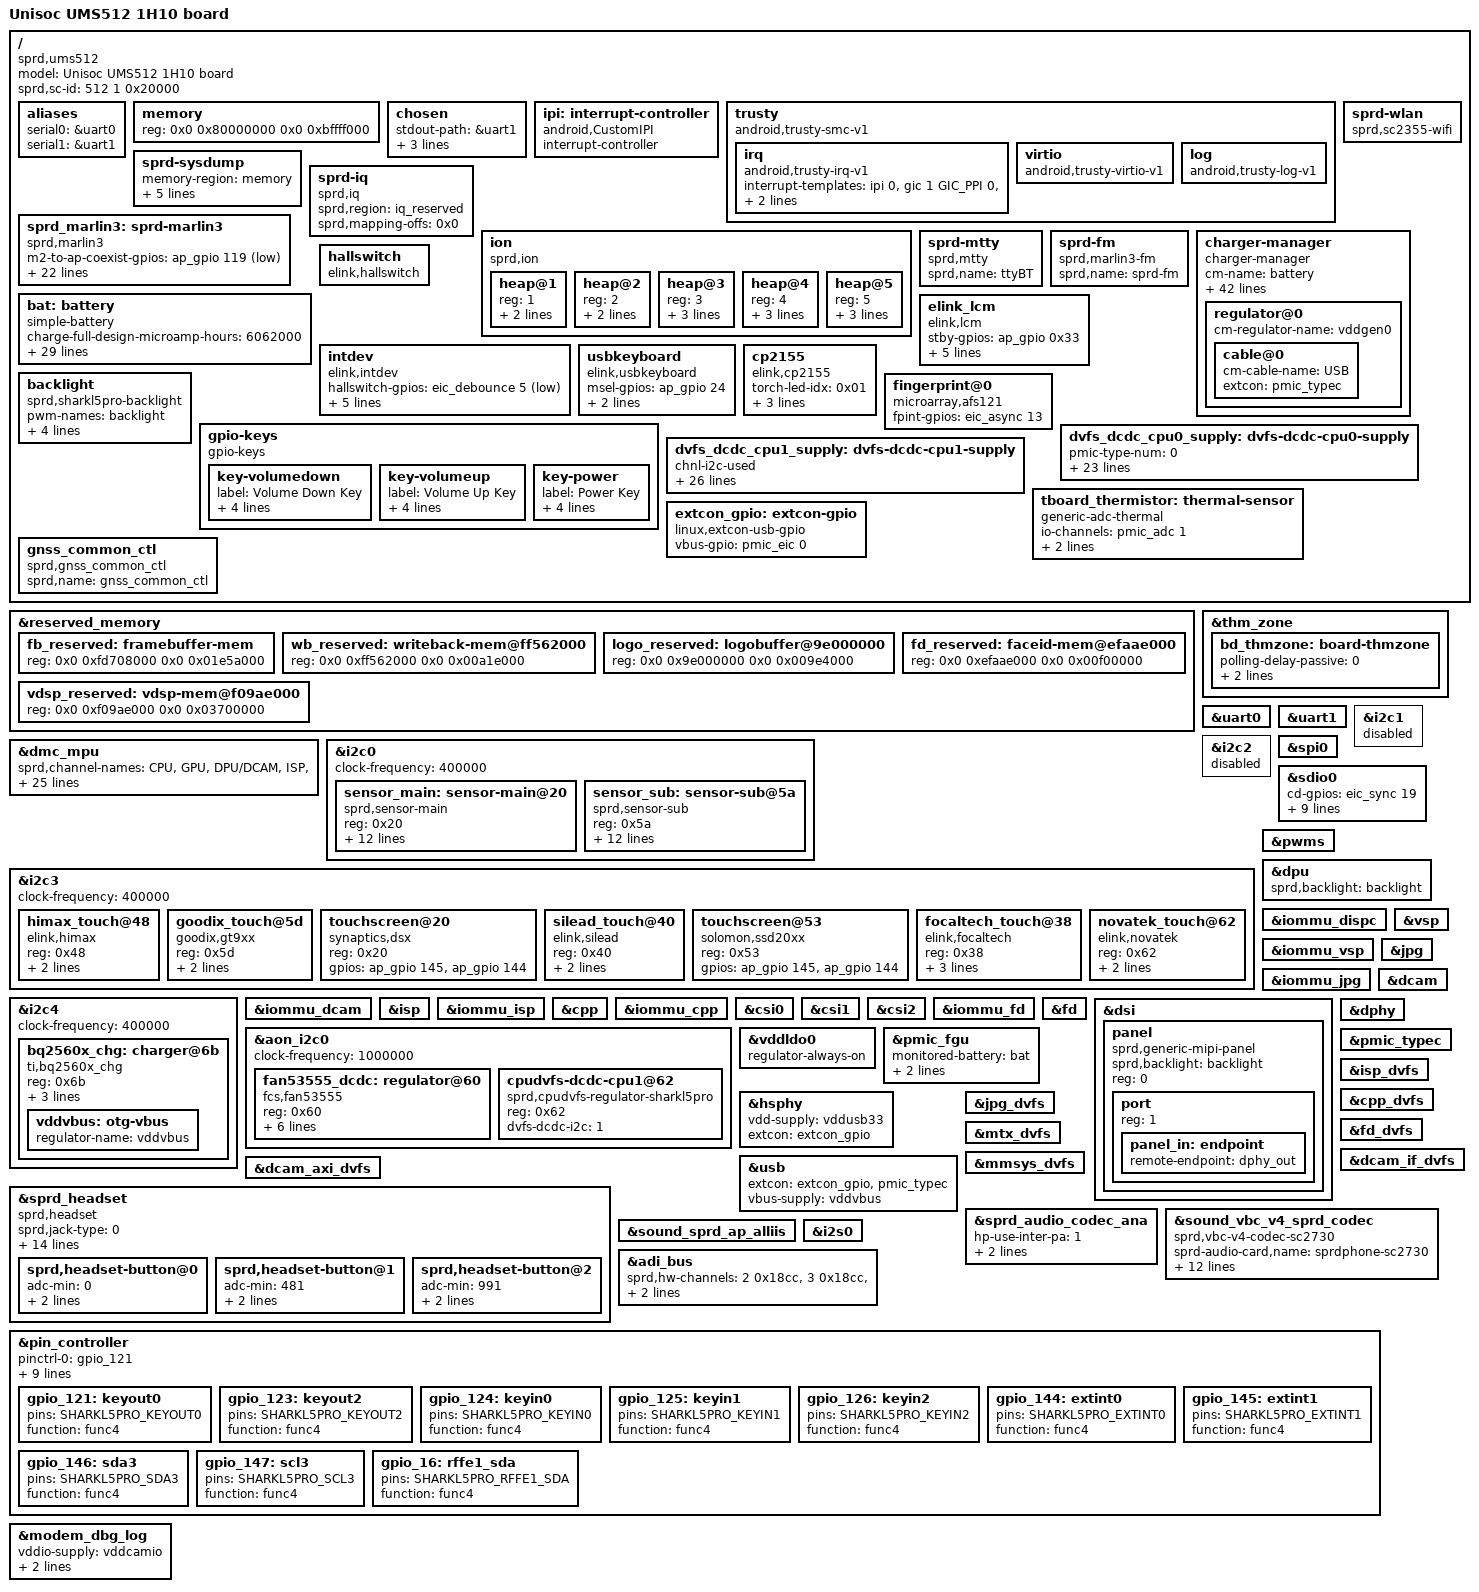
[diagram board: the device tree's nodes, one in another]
// SPDX-License-Identifier: (GPL-2.0+ OR MIT)
/*
 * Unisoc Sharkl5Pro platform DTS file
 *
 * Copyright (C) 2018, Unisoc Communications Inc.
 */

/dts-v1/;

#include <dt-bindings/gpio/gpio.h>
#include <dt-bindings/input/input.h>
#include <dt-bindings/interrupt-controller/irq.h>
#include "aidata-ums512.dtsi"
#include "ums512-t610dvfs.dtsi"
#include "ums512-t618dvfs.dtsi"
#include "sc2730.dtsi"
#include "ums512-mach.dtsi"
#include "ums512-modem.dtsi"
#include "aidata-lcd.dtsi"
#include "sprd-sound-fe-be.dtsi"
#include "extra_sound_card_component.dtsi"

/ {
	model = "Unisoc UMS512 1H10 board";

	compatible = "sprd,ums512";

	sprd,sc-id = <512 1 0x20000>;

	aliases {
		serial0 = &uart0;
		serial1 = &uart1;
	};

/* 3 GB */
	memory: memory {
		device_type = "memory";
		reg = <0x0 0x80000000 0x0 0xbffff000>;
	};

	chosen {
		stdout-path = &uart1;
		bootargs = "earlycon=sprd_serial,0x70100000,115200n8 console=ttyS1,115200n8 loglevel=8 init=/init root=/dev/ram0 rw androidboot.hardware=ums512_1h10 androidboot.dtbo_idx=0 printk.devkmsg=on androidboot.boot_devices=soc/soc:ap-apb/71400000.sdio swiotlb=1 lcd_id=ID8006 lcd_name=tv101wum_ll2_wuxga lcd_base=9e000000 lcd_size=1920x1200 pixel_clock=153600000 logo_bpix=24 androidboot.ddrsize=3072M androidboot.ddrsize.range=[2048,) androidboot.lwfq.type=1 androidboot.auto.efuse=T610 androidboot.auto.chipid=UMS512-AC  sysdump_magic=85500000 modem=shutdown ltemode=lcsfb rfboard.id=0 rfhw.id=32816 crystal=6 32k.less=1 marlin.clktype=1 androidboot.pmic.chipid=2730 modemboot.method=emmcboot  androidboot.verifiedbootstate=orange androidboot.flash.locked=0  androidboot.serialno=AU13T31J045675 androidboot.vbmeta.device=PARTUUID=1.0";
		elink_bootmode = "2";
	};

	ipi: interrupt-controller {
		compatible = "android,CustomIPI";
		#interrupt-cells = <1>;
		interrupt-controller;
	};

	trusty {
		compatible = "android,trusty-smc-v1";
		irq {
			compatible = "android,trusty-irq-v1";
			interrupt-templates = <&ipi 0>,
				<&gic 1 GIC_PPI 0>,
				<&gic 1 GIC_SPI 0>;
			interrupt-ranges = < 0  15 0>,
					<16  31 1>,
					<32 223 2>;
		};

		virtio {
			compatible = "android,trusty-virtio-v1";
		};

		log {
			compatible = "android,trusty-log-v1";
		};
	};
	sprd-sysdump {
		memory-region = <&memory>;
		memory-region-re = <&ddrbist_reserved>, <&cp_reserved>, <&smem_reserved>, <&sensorhub_reserved>, <&scproc_pubpm>, <&audio_reserved>, <&audiodsp_reserved>;
		memory-region-se = <&tos_reserved>, <&sml_reserved>;
	};

	sprd-iq {
		compatible = "sprd,iq";
		sprd,region = <&iq_reserved>;
		sprd,mapping-offs = <0x0>;
	};

	ion: ion {
		compatible = "sprd,ion";
		#address-cells = <1>;
		#size-cells = <0>;

		heap@1 {
			reg = <1>;
			label = "carveout_mm";
			type = <2>;
		};

		heap@2 {
			reg = <2>;
			label = "carveout_overlay";
			type = <2>;
		};

		heap@3 {
			reg = <3>;
			label = "carveout_fb";
			type = <2>;
			memory-region = <&fb_reserved>;
		};

		heap@4 {
			reg = <4>;
			label = "carveout_fd";
			type = <2>;
			memory-region = <&fd_reserved>;
		};

		heap@5 {
			reg = <5>;
			label = "carveout_vdsp";
			type = <2>;
			memory-region = <&vdsp_reserved>;
		};
	};

	sprd-wlan {
		compatible = "sprd,sc2355-wifi";
	};

	sprd_marlin3: sprd-marlin3 {
		compatible = "sprd,marlin3";
		m2-to-ap-coexist-gpios = <&ap_gpio 119 GPIO_ACTIVE_LOW>;
		m2-wakeup-ap-gpios = <&ap_gpio 32 GPIO_ACTIVE_LOW>;
		permit-ap-send-gpios = <&ap_gpio 121 GPIO_ACTIVE_LOW>;
		reset-gpios = <&ap_gpio 95 GPIO_ACTIVE_LOW>;
		enable-gpios = <&ap_gpio 143 GPIO_ACTIVE_LOW>;
		m2-to-ap-irq-gpios = <&ap_gpio 94 GPIO_ACTIVE_LOW>;
		avdd12-supply = <&vddwcn>;
		avdd33-supply = <&vddwifipa>;
		dcxo18-supply = <&vddsim2>;

		clock-names = "clk_32k", "source", "enable";
		clocks = <&aon_clk CLK_AUX0>,
		<&ext_32k>,
		<&aonapb_gate CLK_AUX0_EB>;

		sdhci-name = <&sdio1>;
		sprd,btwf-file-name = "/dev/block/platform/soc/soc:ap-apb/71400000.sdio/by-name/wcnmodem";
		sprd,gnss-file-name = "/dev/block/platform/soc/soc:ap-apb/71400000.sdio/by-name/gnssmodem";
		adma-tx;
		adma-rx;
		/*
		 * bound parameter:
		 * [0]:addr offset, [1]:mask, [2]:unboundval, [3]:boundval
		 */
		avdd12-parent-bound-chip = <0x1a4c 0x1 0x0 0x1>;
		avdd12-bound-wbreq = <0x1ac8 0x1000 0x0 0x1000>;
		avdd33-bound-wbreq = <0x1acc 0x4 0x0 0x4>;
		post-power-on-delay-ms = <20>;
		/* stock U-Boot passes marlin.clktype=1 (TSX); U-Boot here does not */
		xtal-26m-clk-type = "TSX";
	};

	sprd-mtty {
		compatible = "sprd,mtty";
		sprd,name = "ttyBT";
	};

	sprd-fm {
		compatible = "sprd,marlin3-fm";
		sprd,name = "sprd-fm";
	};

	bat: battery {
		compatible = "simple-battery";
		charge-full-design-microamp-hours = <6062000>;
		charge-term-current-microamp = <240000>;
		constant_charge_current_max_microamp = <240000>;
		constant_charge_voltage_max_microvolt = <4352000>;
		factory-internal-resistance-micro-ohms = <88000>;
		voltage-min-design-microvolt = <3450000>;
		ocv-capacity-celsius = <20>;

		ocv-capacity-table-0 = <4311000 100>, <4246000 95>, <4190000 90>,
		<4137000 85>, <4086000 80>, <4039000 75>,
		<3981000 70>, <3955000 65>, <3912000 60>,
		<3867000 55>, <3839000 50>, <3818000 45>,
		<3802000 40>, <3789000 35>, <3777000 30>,
		<3763000 25>, <3746000 20>, <3723000 15>,
		<3696000 10>, <3681000 5>, <3400000 0>;

		capacity-temp-table = <45 99>, <25 100>, <10 100>, <0 100>,
		<(-10) 91>, <(-20) 70>;

		resistance-temp-table = <45 68>, <25 88>, <10 280>, <0 428>,
		<(-10) 1181>, <(-20) 1403>;

		voltage-temp-table = <1066000 800>, <959000 850>, <855000 900>,
		<754000 950>, <660000 1000>, <574000 1050>,
		<497000 1100>, <428000 1150>, <368000 1200>,
		<316000 1250>, <271000 1300>, <232000 1350>,
		<199000 1400>, <170000 1450>, <146000 1500>,
		<126000 1550>, <108000 1600>, <94000 1650>;

		charge-sdp-current-microamp = <500000 500000>;
		charge-dcp-current-microamp = <2000000 2000000>;
		charge-cdp-current-microamp = <1150000 1150000>;
		charge-unknown-current-microamp = <2000000 2000000>;
	};

	charger-manager {
		compatible = "charger-manager";
		cm-name = "battery";
		cm-poll-mode = <2>;
		cm-poll-interval = <15000>;
		cm-battery-stat = <2>;
		cm-capacity-track;

		monitored-battery = <&bat>;

		cm-fullbatt-vchkdrop-ms = <30000>;
		cm-fullbatt-vchkdrop-volt = <60000>;
		cm-fullbatt-voltage = <4352000>;
		cm-fullbatt-current = <240000>;
		cm-fullbatt-capacity = <100>;

		cm-num-chargers = <1>;
		cm-chargers = "bq2560x_charger";
		cm-fuel-gauge = "sc27xx-fgu";

		cm-battery-cold = <0>;
		cm-battery-cold-in-minus;
		cm-battery-hot = <500>;
		cm-battery-temp-diff = <100>;

		cm-charging-max = <21600000>;
		cm-discharging-max = <2700000>;

		cm-wdt-interval = <60>;

		cm-shutdown-voltage = <3100000>;

		cm-tickle-time-out = <1500>;
		cm-one-cap-time = <30>;

		cm-charge-voltage-max = <6500000>;
		cm-charge-voltage-drop = <700000>;

		cm-sdp-jeita-temp-table = <1000 1030 0 4352000>,
		<1150 1180 500000 4352000>,
		<1450 1420 500000 4352000>,
		<1600 1570 500000 4100000>;

		cm-cdp-jeita-temp-table = <1000 1030 0 4352000>,
		<1150 1180 700000 4352000>,
		<1450 1420 1150000 4352000>,
		<1600 1570 700000 4100000>;

		cm-dcp-jeita-temp-table = <1000 1030 0 4352000>,
		<1150 1180 700000 4352000>,
		<1450 1420 2000000 4352000>,
		<1600 1570 700000 4100000>;

		cm-unknown-jeita-temp-table = <1000 1030 0 4352000>,
		<1150 1180 700000 4352000>,
		<1450 1420 2000000 4352000>,
		<1600 1570 700000 4100000>;

		regulator@0 {
			cm-regulator-name = "vddgen0";

			cable@0 {
				cm-cable-name = "USB";
				extcon = <&pmic_typec>;
			};
		};
	};

	elink_lcm {
		compatible = "elink,lcm";
		stby-gpios = <&ap_gpio 0x33 GPIO_ACTIVE_HIGH>;
		ts_rst-gpios = <&ap_gpio 0x91 GPIO_ACTIVE_HIGH>;
		dvdd-gpios = <&ap_gpio 0x57 GPIO_ACTIVE_HIGH>;
		vghl-gpios = <&ap_gpio 0x82 GPIO_ACTIVE_HIGH>;
		rst-gpios = <&ap_gpio 0x32 GPIO_ACTIVE_HIGH>;
		avdd-gpios = <&ap_gpio 0x1c GPIO_ACTIVE_HIGH>;
	};

	hallswitch {
		compatible = "elink,hallswitch";
		status = "okay";
	};

	intdev {
		compatible = "elink,intdev";
		status = "okay";

		hallswitch-gpios  = <&eic_debounce 5 GPIO_ACTIVE_LOW>;
		usbkeyboard-gpios = <&eic_debounce 12 GPIO_ACTIVE_LOW>;

		hallswitch_flag      = <0x08>;
		usbkeyboard_flag     = <0x08>;
		hallswitch_debounce  = <0xfa00>;
		usbkeyboard_debounce = <0xfa00>;
	};

	usbkeyboard {
		compatible = "elink,usbkeyboard";
		status = "okay";

		msel-gpios   = <&ap_gpio 24 GPIO_ACTIVE_HIGH>;  /* 0x18 -> Pin 24 */
		dk_5v-gpios  = <&ap_gpio 114 GPIO_ACTIVE_HIGH>; /* 0x72 -> Pin 114 */
		usb_5v-gpios = <&ap_gpio 112 GPIO_ACTIVE_HIGH>; /* 0x70 -> Pin 112 */
	};

	backlight: backlight {
		compatible = "sprd,sharkl5pro-backlight";
		status = "okay";

		pwm-names = "backlight";
		pwms = <&pwms 2 40000>;

		default-brightness-level = <512>;
		sprd,max-brightness-level = <1023>;
		sprd,brightness-scale     = <1023>;
	};

	gpio-keys {
		compatible = "gpio-keys";
		status = "okay";

		key-volumedown {
			label = "Volume Down Key";
			linux,code = <114>; /* KEY_VOLUMEDOWN */
			debounce-interval = <2>;
			gpios = <&ap_gpio 124 GPIO_ACTIVE_LOW>;
			wakeup-source;
		};

		key-volumeup {
			label = "Volume Up Key";
			linux,code = <115>; /* KEY_VOLUMEUP */
			debounce-interval = <2>;
			gpios = <&ap_gpio 125 GPIO_ACTIVE_LOW>;
			wakeup-source;
		};

		key-power {
			label = "Power Key";
			linux,code = <116>; /* KEY_POWER */
			debounce-interval = <2>;
			gpios = <&pmic_eic 1 GPIO_ACTIVE_LOW>;
			wakeup-source;
		};
	};

	cp2155 {
		compatible = "elink,cp2155";
		torch-led-idx = <0x01>;
		flash-ic = <0x86b>;
		flash-en-gpios = <&ap_gpio 139 GPIO_ACTIVE_HIGH>;
		flash-torch-en-gpios = <&ap_gpio 137 GPIO_ACTIVE_HIGH>;
	};

	fingerprint@0 {
		fpint-gpios = <&eic_async 13 GPIO_ACTIVE_HIGH>;
		compatible = "microarray,afs121";
	};

	dvfs_dcdc_cpu0_supply: dvfs-dcdc-cpu0-supply {
		pmic-type-num = <0>;
		slew-rate = <9375>; /* 9375uV/us */
		top-dvfs-adi-state = <0x70 0 0xf>;
		voltage-grade-num = <7>;
		voltage-grade = <0 0xf0 0xf4 0 0x1ff>,
			<1 0xf0 0xf4 9 0x1ff>,
			<2 0x100 0xf4 18 0x1ff>,
			<3 0x110 0xf8 0 0x1ff>,
			<4 0x120 0xf8 9 0x1ff>,
			<5 0x130 0xf8 18 0x1ff>,
			<6 0x140 0xfc 0 0x1ff>;
		voltage-up-delay = <50 0x58 0 0xffff 0x600>,
			<100 0x58 16 0xffff 0xa00>,
			<150 0x54 0 0xffff 0xf00>,
			<200 0x54 16 0xffff 0x1400>,
			<250 0x50 0 0xffff 0x1900>,
			<300 0x50 16 0xffff 0x1e00>,
			<350 0x110 0 0xffff 0x2300>;
		voltage-down-delay = <50 0x64 0 0xffff 0x600>,
			<100 0x64 16 0xffff 0xa00>,
			<150 0x60 0 0xffff 0xf00>,
			<200 0x60 16 0xffff 0x1400>,
			<250 0x5c 0 0xffff 0x1900>,
			<300 0x5c 16 0xffff 0x1e00>,
			<350 0x114 0 0xffff 0x2300>;
		tuning-latency-us = <0>;
		chnl-in-i2c = <0>;
	};
	dvfs_dcdc_cpu1_supply: dvfs-dcdc-cpu1-supply {
		chnl-i2c-used;
		third-pmic-used;
		pmic-type-num = <2>;
		slew-rate = <4000>; /* 4000uV/us */
		supply-type-sel = <0x120 0 1>;
		top-dvfs-i2c-state = <0x9c 4 0xf>;
		voltage-grade-num = <6>;
		voltage-grade = <0 0x0f 0x12c 0 0x7f>,
			<1 0x14 0x12c 7 0x7f>,
			<2 0x19 0x12c 14 0x7f>,
			<3 0x1e 0x12c 21 0x7f>,
			<4 0x23 0x130 0 0x7f>,
			<5 0x28 0x130 7 0x7f>;
		voltage-up-delay = <50 0x84 0 0xffff 0x1600>,
			<100 0x84 16 0xffff 0x1a00>,
			<150 0x80 0 0xffff 0x1f00>,
			<200 0x80 16 0xffff 0x2400>,
			<250 0x7c 0 0xffff 0x2900>,
			<300 0x7c 16 0xffff 0x2e00>,
			<350 0x118 0 0xffff 0x3300>;
		voltage-down-delay = <50 0x90 0 0xffff 0x600>,
			<100 0x90 16 0xffff 0xa00>,
			<150 0x8c 0 0xffff 0xf00>,
			<200 0x8c 16 0xffff 0x1400>,
			<250 0x88 0 0xffff 0x1900>,
			<300 0x88 16 0xffff 0x1e00>,
			<350 0x11c 0 0xffff 0x2300>;
		tuning-latency-us = <0>;
		chnl-in-i2c = <1>;
	};

	tboard_thermistor:thermal-sensor {
		compatible = "generic-adc-thermal";
		#thermal-sensor-cells = <0>;
		io-channels = <&pmic_adc 1>;
		io-channel-names = "sensor-channel";
		temperature-lookup-table = <	(-39742) 1131
						(-29777) 1110
						(-19480) 1074
						(-4679) 983
						10110 838
						24805 654
						44922 413
						54903 316
						64895 238
						74884 178
						84883 133
						94883 100
						104880 75
						114889 57
						124872 43 >;
	};

	extcon_gpio: extcon-gpio {
		compatible = "linux,extcon-usb-gpio";
		vbus-gpio = <&pmic_eic 0 GPIO_ACTIVE_HIGH>;
	};

	gnss_common_ctl {
		compatible = "sprd,gnss_common_ctl";
		sprd,name = "gnss_common_ctl";
	};

};

&reserved_memory {
	fb_reserved: framebuffer-mem {
		reg = <0x0 0xfd708000 0x0 0x01e5a000>;
	};

	wb_reserved: writeback-mem@ff562000 {
		reg = <0x0 0xff562000 0x0 0x00a1e000>;
	};

	logo_reserved: logobuffer@9e000000{
		reg = <0x0 0x9e000000 0x0 0x009e4000>;
	};

	fd_reserved: faceid-mem@efaae000 {
		reg = <0x0 0xefaae000 0x0 0x00f00000>;
	};

	vdsp_reserved: vdsp-mem@f09ae000 {
		reg = <0x0 0xf09ae000 0x0 0x03700000>;
	};
};

&thm_zone {
	bd_thmzone: board-thmzone {
		polling-delay-passive = <0>;
		polling-delay = <0>;
		thermal-sensors = <&tboard_thermistor>;
	};
};

&dmc_mpu {
	status = "okay";
	sprd,channel-names =
		"CPU", "GPU", "DPU/DCAM","ISP",
		"AP/VSP/AON", "WTLCP", "PUBCP/AUDCP",
		"SHARED0", "SHARED1", "SHARED2",
		"SHARED3", "SHARED4", "SHARED5",
		"SHARED6", "SHARED7", "SHARED8";
	sprd,ranges = <0 0 0 0>, <0 0 0 0>, <0 0 0 0>,
		<0 0 0 0>, <0 0 0 0>, <0 0x87400000 0 0x94000000>,
		<0 0x87400000 0 0x94000000>, <0 0 0 0>, <0 0 0 0>,
		<0 0 0 0>, <0 0 0 0>, <0 0 0 0>,
		<0 0 0 0>, <0 0 0 0>, <0 0 0 0>,
		<0 0 0 0>;
	sprd,chn-config =
		<DISABLE MON_INSIDE MON_WRITE>,
		<DISABLE MON_INSIDE MON_WRITE>,
		<DISABLE MON_INSIDE MON_WRITE>,
		<DISABLE MON_INSIDE MON_WRITE>,
		<DISABLE MON_INSIDE MON_WRITE>,
		<ENABLE MON_OUTSIDE MON_WRITE>,
		<ENABLE MON_OUTSIDE MON_WRITE>,
		<DISABLE MON_INSIDE MON_WRITE>,
		<DISABLE MON_INSIDE MON_WRITE>,
		<DISABLE MON_INSIDE MON_WRITE>,
		<DISABLE MON_INSIDE MON_WRITE>,
		<DISABLE MON_INSIDE MON_WRITE>,
		<DISABLE MON_INSIDE MON_WRITE>,
		<DISABLE MON_INSIDE MON_WRITE>,
		<DISABLE MON_INSIDE MON_WRITE>,
		<DISABLE MON_INSIDE MON_WRITE>;
	sprd,panic;
};

&uart0 {
	status = "okay";
};

&uart1 {
	status = "okay";
};

&i2c0 {
	status = "okay";
	clock-frequency = <400000>;

	sensor_main: sensor-main@20 {
		compatible = "sprd,sensor-main";
		reg = <0x20>;
		clock-names = "clk_src","sensor_eb",
			"clk_96m","clk_76m8",
			"clk_48m","clk_26m";
		clocks = <&mm_clk CLK_SENSOR0>,<&mm_gate CLK_MM_SENSOR0_EB>,
				<&pll2 CLK_TWPLL_96M>,<&pll2 CLK_TWPLL_76M8>,
				<&pll2 CLK_TWPLL_48M>,<&ext_26m>;
		vddio-supply = <&vddcamio>;
		vddcama-supply = <&vddcama0>;
		vddcamd-supply = <&vddcamd0>;
		vddcammot-supply = <&vddcammot>;
		reset-gpios = <&ap_gpio 44 0>;
		power-down-gpios = <&ap_gpio 46 0>;
		sprd,phyid = <0>;
		csi = <&csi0>;
	};

	sensor_sub: sensor-sub@5a {
		compatible = "sprd,sensor-sub";
		reg = <0x5a>;
		clock-names = "clk_src","sensor_eb",
		"clk_96m","clk_76m8",
		"clk_48m","clk_26m";
		clocks = <&mm_clk CLK_SENSOR1>,<&mm_gate CLK_MM_SENSOR1_EB>,
		<&pll2 CLK_TWPLL_96M>,<&pll2 CLK_TWPLL_76M8>,
		<&pll2 CLK_TWPLL_48M>,<&ext_26m>;
		vddio-supply = <&vddcamio>;
		vddcama-supply = <&vddcama0>;
		vddcamd-supply = <&vddcamd0>;
		vddcammot-supply = <&vddcammot>;
		reset-gpios = <&ap_gpio 45 0>;
		power-down-gpios = <&ap_gpio 47 0>;
		sprd,phyid = <1>;
		csi = <&csi1>;
	};
};

&i2c1 {
	status = "disabled";
};

&i2c2 {
	status = "disabled";
};

&i2c3 {
	status = "okay";
	clock-frequency = <400000>;

	himax_touch@48 {
		compatible = "elink,himax";
		reg = <0x48>;
		irq-gpios = <&ap_gpio 144 GPIO_ACTIVE_HIGH>;
		rst-gpios = <&ap_gpio 145 GPIO_ACTIVE_HIGH>;
	};

	goodix_touch@5d {
		compatible = "goodix,gt9xx";
		reg = <0x5d>;
		irq-gpios = <&ap_gpio 144 GPIO_ACTIVE_HIGH>;
		rst-gpios = <&ap_gpio 145 GPIO_ACTIVE_HIGH>;
	};

	touchscreen@20 {
		compatible = "synaptics,dsx";
		reg = <0x20>;
		gpios = <&ap_gpio 145 GPIO_ACTIVE_HIGH &ap_gpio 144 GPIO_ACTIVE_HIGH>;
	};

	silead_touch@40 {
		compatible = "elink,silead";
		reg = <0x40>;
		irq-gpios = <&ap_gpio 144 GPIO_ACTIVE_HIGH>;
		rst-gpios = <&ap_gpio 145 GPIO_ACTIVE_HIGH>;
	};

	touchscreen@53 {
		compatible = "solomon,ssd20xx";
		reg = <0x53>;
		gpios = <&ap_gpio 145 GPIO_ACTIVE_HIGH &ap_gpio 144 GPIO_ACTIVE_HIGH>;
	};

	focaltech_touch@38 {
		compatible = "elink,focaltech";
		reg = <0x38>;
		irq-gpios = <&ap_gpio 144 GPIO_ACTIVE_HIGH>;
		rst-gpios = <&ap_gpio 145 GPIO_ACTIVE_HIGH>;
		stdby-gpios = <&ap_gpio 135 GPIO_ACTIVE_HIGH>;
	};

	novatek_touch@62 {
		compatible = "elink,novatek";
		reg = <0x62>;
		irq-gpios = <&ap_gpio 144 GPIO_ACTIVE_HIGH>;
		rst-gpios = <&ap_gpio 145 GPIO_ACTIVE_HIGH>;
	};
};

&i2c4 {
	status = "okay";
	clock-frequency = <400000>;

	bq2560x_chg: charger@6b {
		compatible = "ti,bq2560x_chg";
		reg = <0x6b>;
		phys = <&hsphy>;
		monitored-battery = <&bat>;
		extcon = <&extcon_gpio>;

		vddvbus: otg-vbus {
			regulator-name = "vddvbus";
		};
	};
};

&spi0 {
	/*used for fingerprint sensor*/
	status = "okay";
};

&sdio0 {
	cd-gpios = <&eic_sync 19 GPIO_ACTIVE_HIGH>;
	syscons = <&aon_apb_regs REG_AON_APB_RF_AP_SDIO0_PHY_CTRL MASK_AON_APB_RF_AP_SDIO0_CARD_PRESENT_32K>,
		  <&aon_apb_regs REG_AON_APB_RF_AP_SDIO0_PHY_CTRL MASK_AON_APB_RF_AP_SDIO0_CARD_PROTECT_32K>,
		  <&aon_apb_regs REG_AON_APB_RF_AP_SDIO0_PHY_CTRL MASK_AON_APB_RF_AP_SDIO0_CARDDET_DBNC_EN_32K>,
		  <&aon_apb_regs REG_AON_APB_RF_AP_SDIO0_PHY_CTRL MASK_AON_APB_RF_AP_SDIO0_CARDDET_DBNC_THD_32K>;
	syscon-names = "sd_detect_pol",
		       "sd_hotplug_protect_en",
		       "sd_hotplug_debounce_en",
		       "sd_hotplug_debounce_cn";

};

&pwms {
	status = "okay";
};

&dpu {
	status = "okay";
	sprd,backlight = <&backlight>;
};

&iommu_dispc {
	status = "okay";
};

&vsp {
	status = "okay";
};

&iommu_vsp {
	status = "okay";
};

&jpg {
	status = "okay";
};

&iommu_jpg {
	status = "okay";
};

&dcam {
	status = "okay";
};

&iommu_dcam {
	status = "okay";
};

&isp {
	status = "okay";
};

&iommu_isp {
	status = "okay";
};

&cpp {
	status = "okay";
};

&iommu_cpp {
	status = "okay";
};

&csi0 {
	status = "okay";
};

&csi1 {
	status = "okay";
};

&csi2 {
	status = "okay";
};

&iommu_fd {
	status = "okay";
};

&fd {
	status = "okay";
};

&dsi {
	status = "okay";
	#address-cells = <1>;
	#size-cells = <0>;

	panel: panel {
		compatible = "sprd,generic-mipi-panel";
		sprd,backlight = <&backlight>;
		#address-cells = <1>;
		#size-cells = <0>;
		reg = <0>;

		port {
			reg = <1>;
			panel_in: endpoint {
				remote-endpoint = <&dphy_out>;
			};
		};
	};
};

&dphy {
	status = "okay";
};

&aon_i2c0 {
	status = "okay";
	clock-frequency = <1000000>;

	fan53555_dcdc: regulator@60 {
		compatible = "fcs,fan53555";
		reg = <0x60>;
		regulator-name = "fan53555";
		regulator-min-microvolt = <600000>;
		regulator-max-microvolt = <1230000>;
		regulator-ramp-delay = <64000>;
		regulator-always-on;
		fcs,suspend-voltage-selector = <1>;
	};

	/* A virtual i2c device */
	cpudvfs-dcdc-cpu1@62{
		compatible = "sprd,cpudvfs-regulator-sharkl5pro";
		reg = <0x62>;
		dvfs-dcdc-i2c = <1>;
	};
};

&vddldo0 {
	regulator-always-on;
};

&pmic_fgu {
	monitored-battery = <&bat>;
	sprd,calib-resistance-real = <10000>;
	sprd,calib-resistance-spec = <20000>;
};

&hsphy {
	vdd-supply = <&vddusb33>;
	extcon = <&extcon_gpio>;
};

&usb {
	extcon = <&extcon_gpio>, <&pmic_typec>;
	vbus-supply = <&vddvbus>;
};

&pmic_typec {
	status = "okay";
};

&isp_dvfs {
	status = "okay";
};

&cpp_dvfs {
	status = "okay";
};

&jpg_dvfs {
	status = "okay";
};

&fd_dvfs {
	status = "okay";
};

&mtx_dvfs {
	status = "okay";
};

&dcam_if_dvfs {
	status = "okay";
};

&dcam_axi_dvfs {
	status = "okay";
};

&mmsys_dvfs {
	status = "okay";
};

&sprd_headset {
	compatible = "sprd,headset";
	status = "okay";

	sprd,jack-type = <0>;
	sprd,debounce-interval = <10>;          /* 0x0a */
	sprd,3pole-adc-threshold = <112>;       /* 0x70 */
	sprd,adc-gnd = <328>;                  /* 0x148 */
	sprd,half-adc-gnd = <100>;             /* 0x64 */
	sprd,coefficient = <0xd7f28>;          /* 884520 */
	sprd,irq-threshold-button = <4>;       /* 0x04 */

	/* ADC & GPIO */
	io-channels = <&pmic_adc 20>;          /* 0x14 = Channel 20 */
	io-channel-names = "headmic_in_little";

	gpios = <&pmic_eic 6 GPIO_ACTIVE_HIGH>;
	gpio-names = "aud_int_all";

	/* SoC GPIO */
	mic-gpios = <&ap_gpio 25 GPIO_ACTIVE_HIGH>; /* 0x19 = GPIO 25 */
	lr-gpios = <&ap_gpio 26 GPIO_ACTIVE_HIGH>;  /* 0x1a = GPIO 26 */

	/* NVMEM */
	nvmem-cells = <&headset_adc_fir>, <&headset_adc_sec>;
	nvmem-cell-names = "hp_adc_fir_calib", "hp_adc_sec_calib";

	/* Headset button */
	sprd,headset-button@0 {
		adc-min = <0>;
		adc-max = <480>;                /* 0x1e0 */
		code = <226>;                   /* 0xe2 (KEY_MEDIA) */
	};

	sprd,headset-button@1 {
		adc-min = <481>;                /* 0x1e1 */
		adc-max = <990>;                /* 0x3de */
		code = <115>;                   /* 0x73 (KEY_VOLUMEUP) */
	};

	sprd,headset-button@2 {
		adc-min = <991>;                /* 0x3df */
		adc-max = <2500>;               /* 0x9c4 */
		code = <114>;                   /* 0x72 (KEY_VOLUMEDOWN) */
	};
};

/* Analog Codec */
&sprd_audio_codec_ana {
	status = "okay";
	hp-use-inter-pa = <1>;
	fixed-sample-rate = <48000 48000 48000>;
	digital-codec = <&sprd_audio_codec_dig>;
};

/* VBC v4 Sound Card / sound@0 Overrides */
&sound_vbc_v4_sprd_codec {
	compatible = "sprd,vbc-v4-codec-sc2730";
	status = "okay";
	sprd-audio-card,name = "sprdphone-sc2730";
	sprd-audio-card,headset = <&sprd_headset>;
	sprd,syscon-agcp-ahb = <&audcp_ahb_regs>;

	sprd,spk-ext-pa-names = "ext_spk_r";
	sprd,spk-ext-pa-gpio = <&ap_gpio 29 GPIO_ACTIVE_HIGH>;
	sprd,spk-ext-pa-info = <0x00 0x00 0x04 0x00>;

	sprd-audio-card,widgets =
	"Headphone", "inter HP PA",
	"Speaker", "inter Ear PA";

	sprd-audio-card,routing =
	"HPMIC Pin", "HP Mic Jack",
	"MIC Pin", "Mic Jack",
	"MIC2 Pin", "Aux Mic Jack",
	"inter HP PA", "HP Pin",
	"Ext Spk", "HP Pin",
	"DMIC Pin", "DMic Jack",
	"DMIC1 Pin", "DMic1 Jack",
	"inter Ear PA", "EAR Pin";

};

&sound_sprd_ap_alliis {
	status = "okay";
};

&i2s0 {
	status = "okay";
};

&adi_bus {
	sprd,hw-channels = <2 0x18cc>, <3 0x18cc>, <13 0x1854>, <15 0x1874>,
			 <17 0x1844>,<19 0x1844>, <21 0x1864>, <30 0x1820>,
			 <35 0x19b8>, <39 0x19ac>;
};

&pin_controller {
	pinctrl-names =
	"gpio_121", "gpio_123", "gpio_124", "gpio_125", "gpio_126",
	"gpio_144", "gpio_145", "gpio_146", "gpio_147", "gpio_16";

	pinctrl-0 = <&gpio_121>;
	pinctrl-1 = <&gpio_123>;
	pinctrl-2 = <&gpio_124>;
	pinctrl-3 = <&gpio_125>;
	pinctrl-4 = <&gpio_126>;
	pinctrl-5 = <&gpio_144>;
	pinctrl-6 = <&gpio_145>;
	pinctrl-7 = <&gpio_146>;
	pinctrl-8 = <&gpio_147>;
	pinctrl-9 = <&gpio_16>;

	gpio_121: keyout0 {
		pins = "SHARKL5PRO_KEYOUT0";
		function = "func4";
	};

	gpio_123: keyout2 {
		pins = "SHARKL5PRO_KEYOUT2";
		function = "func4";
	};

	gpio_124: keyin0 {
		pins = "SHARKL5PRO_KEYIN0";
		function = "func4";
	};

	gpio_125: keyin1 {
		pins = "SHARKL5PRO_KEYIN1";
		function = "func4";
	};

	gpio_126: keyin2 {
		pins = "SHARKL5PRO_KEYIN2";
		function = "func4";
	};

	gpio_144: extint0 {
		pins = "SHARKL5PRO_EXTINT0";
		function = "func4";
	};

	gpio_145: extint1 {
		pins = "SHARKL5PRO_EXTINT1";
		function = "func4";
	};

	gpio_146: sda3 {
		pins = "SHARKL5PRO_SDA3";
		function = "func4";
	};

	gpio_147: scl3 {
		pins = "SHARKL5PRO_SCL3";
		function = "func4";
	};

	gpio_16: rffe1_sda {
		pins = "SHARKL5PRO_RFFE1_SDA";
		function = "func4";
	};
};

&modem_dbg_log {
	vddio-supply = <&vddcamio>;
	mipi-switch-en-gpios = <&ap_gpio 55 GPIO_ACTIVE_HIGH>;
	mipi-switch-mode-gpios = <&ap_gpio 8 GPIO_ACTIVE_HIGH>;
};
